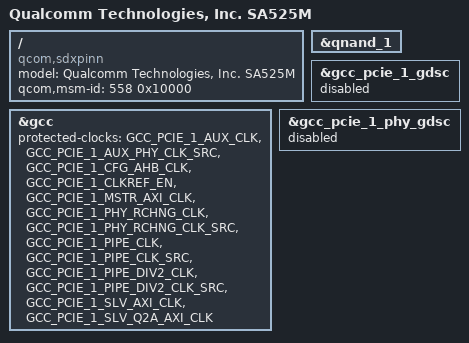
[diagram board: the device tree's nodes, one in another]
#include "sdxpinn.dtsi"

/ {
	model = "Qualcomm Technologies, Inc. SA525M";
	compatible = "qcom,sdxpinn";
	qcom,msm-id=<558 0x10000> ;
};

&qnand_1 {
	status = "ok";
};

&gcc {
	protected-clocks = <GCC_PCIE_1_AUX_CLK>, <GCC_PCIE_1_AUX_PHY_CLK_SRC>,
		<GCC_PCIE_1_CFG_AHB_CLK>, <GCC_PCIE_1_CLKREF_EN>,
		<GCC_PCIE_1_MSTR_AXI_CLK>, <GCC_PCIE_1_PHY_RCHNG_CLK>,
		<GCC_PCIE_1_PHY_RCHNG_CLK_SRC>, <GCC_PCIE_1_PIPE_CLK>,
		<GCC_PCIE_1_PIPE_CLK_SRC>, <GCC_PCIE_1_PIPE_DIV2_CLK>,
		<GCC_PCIE_1_PIPE_DIV2_CLK_SRC>, <GCC_PCIE_1_SLV_AXI_CLK>,
		<GCC_PCIE_1_SLV_Q2A_AXI_CLK>;
};

&gcc_pcie_1_gdsc {
	status = "disabled";
};

&gcc_pcie_1_phy_gdsc {
	status = "disabled";
};
